# ATSAM3SD8B register map
Vendor: Atmel; File version: 0
CPU: CM3 r2p0, selectable endian, no MPU, no FPU, 0x4 interrupt priority bits, 0x0 interrupts
Registers are 32-bit, read-write, no defined reset value unless marked. A register's access mark holds for its fields unless they carry their own. Offsets are from the block's base; [hi:lo] are bit positions; {n}, {i} and the like mark numbered series.

## ADC — Analog-to-Digital Converter
Base 0x40038000; register names take the prefix ADC_
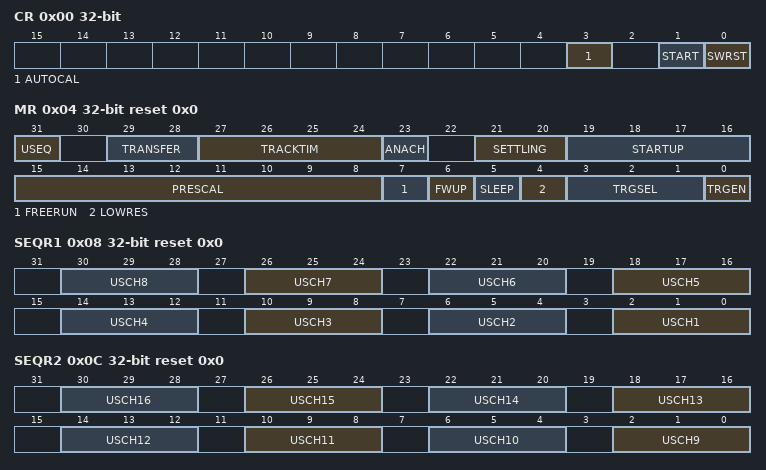
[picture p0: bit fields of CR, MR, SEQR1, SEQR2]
0x00 CR wo — Control Register
  [3] AUTOCAL — Automatic Calibration of ADC
  [1] START — Start Conversion
  [0] SWRST — Software Reset
0x04 MR reset 0x0 — Mode Register
  [31] USEQ — Use Sequence Enable
    0=NUM_ORDER (Normal Mode: The controller converts channels in a simple numeric order.); 1=REG_ORDER (User Sequence Mode: The sequence respects what is defined in ADC_SEQR1 and ADC_SEQR2 registers.)
  [29:28] TRANSFER — Transfer Period
  [27:24] TRACKTIM — Tracking Time
  [23] ANACH — Analog Change
    0=NONE (No analog change on channel switching: DIFF0, GAIN0 and OFF0 are used for all channels); 1=ALLOWED (Allows different analog settings for each channel. See ADC_CGR and ADC_COR Registers)
  [21:20] SETTLING — Analog Settling Time
    0=AST3 (3 periods of ADCClock); 1=AST5 (5 periods of ADCClock); 2=AST9 (9 periods of ADCClock); 3=AST17 (17 periods of ADCClock)
  [19:16] STARTUP — Start Up Time
    0=SUT0 (0 periods of ADCClock); 1=SUT8 (8 periods of ADCClock); 2=SUT16 (16 periods of ADCClock); 3=SUT24 (24 periods of ADCClock); 4=SUT64 (64 periods of ADCClock); 5=SUT80 (80 periods of ADCClock); 6=SUT96 (96 periods of ADCClock); 7=SUT112 (112 periods of ADCClock); 8=SUT512 (512 periods of ADCClock); 9=SUT576 (576 periods of ADCClock); 10=SUT640 (640 periods of ADCClock); 11=SUT704 (704 periods of ADCClock); 12=SUT768 (768 periods of ADCClock); 13=SUT832 (832 periods of ADCClock); 14=SUT896 (896 periods of ADCClock); 15=SUT960 (960 periods of ADCClock)
  [15:8] PRESCAL — Prescaler Rate Selection
  [7] FREERUN — Free Run Mode
    0=OFF (Normal Mode); 1=ON (Free Run Mode: Never wait for any trigger.)
  [6] FWUP — Fast Wake Up
    0=OFF (Normal Sleep Mode: The sleep mode is defined by the SLEEP bit); 1=ON (Fast Wake Up Sleep Mode: The Voltage reference is ON between conversions and ADC Core is OFF)
  [5] SLEEP — Sleep Mode
    0=NORMAL (Normal Mode: The ADC Core and reference voltage circuitry are kept ON between conversions); 1=SLEEP (Sleep Mode: The ADC Core and reference voltage circuitry are OFF between conversions)
  [4] LOWRES — Resolution
    0=BITS_12 (12-bit resolution); 1=BITS_10 (10-bit resolution)
  [3:1] TRGSEL — Trigger Selection
    0=ADC_TRIG0 (External trigger); 1=ADC_TRIG1 (TIO Output of the Timer Counter Channel 0); 2=ADC_TRIG2 (TIO Output of the Timer Counter Channel 1); 3=ADC_TRIG3 (TIO Output of the Timer Counter Channel 2); 4=ADC_TRIG4 (PWM Event Line 0); 5=ADC_TRIG5 (PWM Event Line 1)
  [0] TRGEN — Trigger Enable
    0=DIS (Hardware triggers are disabled. Starting a conversion is only possible by software.); 1=EN (Hardware trigger selected by TRGSEL field is enabled.)
0x08 SEQR1 reset 0x0 — Channel Sequence Register 1
  [4n-2:4n-4] USCH{n} (n=1..8) — User Sequence Number {n}
0x0C SEQR2 reset 0x0 — Channel Sequence Register 2
  [4n-34:4n-36] USCH{n} (n=9..16) — User Sequence Number {n}
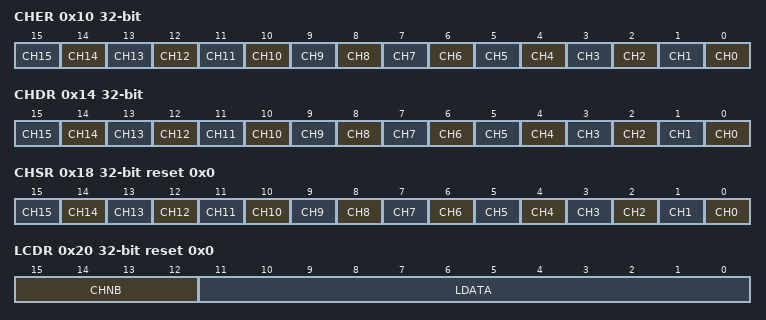
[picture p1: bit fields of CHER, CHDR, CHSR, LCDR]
0x10 CHER wo — Channel Enable Register
  [n] CH{n} (n=0..15) — Channel {n} Enable
0x14 CHDR wo — Channel Disable Register
  [n] CH{n} (n=0..15) — Channel {n} Disable
0x18 CHSR ro reset 0x0 — Channel Status Register
  [n] CH{n} (n=0..15) — Channel {n} Status
0x20 LCDR ro reset 0x0 — Last Converted Data Register
  [15:12] CHNB — Channel Number
  [11:0] LDATA — Last Data Converted
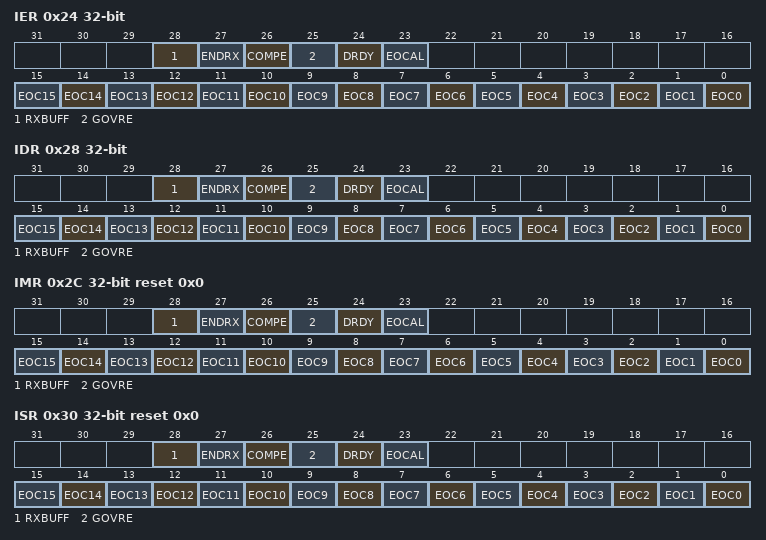
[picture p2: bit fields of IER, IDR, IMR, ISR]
0x24 IER wo — Interrupt Enable Register
  [28] RXBUFF — Receive Buffer Full Interrupt Enable
  [27] ENDRX — End of Receive Buffer Interrupt Enable
  [26] COMPE — Comparison Event Interrupt Enable
  [25] GOVRE — General Overrun Error Interrupt Enable
  [24] DRDY — Data Ready Interrupt Enable
  [23] EOCAL — End of Calibration Sequence
  [n] EOC{n} (n=0..15) — End of Conversion Interrupt Enable {n}
0x28 IDR wo — Interrupt Disable Register
  [28] RXBUFF — Receive Buffer Full Interrupt Disable
  [27] ENDRX — End of Receive Buffer Interrupt Disable
  [26] COMPE — Comparison Event Interrupt Disable
  [25] GOVRE — General Overrun Error Interrupt Disable
  [24] DRDY — Data Ready Interrupt Disable
  [23] EOCAL — End of Calibration Sequence
  [n] EOC{n} (n=0..15) — End of Conversion Interrupt Disable {n}
0x2C IMR ro reset 0x0 — Interrupt Mask Register
  [28] RXBUFF — Receive Buffer Full Interrupt Mask
  [27] ENDRX — End of Receive Buffer Interrupt Mask
  [26] COMPE — Comparison Event Interrupt Mask
  [25] GOVRE — General Overrun Error Interrupt Mask
  [24] DRDY — Data Ready Interrupt Mask
  [23] EOCAL — End of Calibration Sequence
  [n] EOC{n} (n=0..15) — End of Conversion Interrupt Mask {n}
0x30 ISR ro reset 0x0 — Interrupt Status Register
  [28] RXBUFF — RX Buffer Full
  [27] ENDRX — End of RX Buffer
  [26] COMPE — Comparison Error
  [25] GOVRE — General Overrun Error
  [24] DRDY — Data Ready
  [23] EOCAL — End of Calibration Sequence
  [n] EOC{n} (n=0..15) — End of Conversion {n}
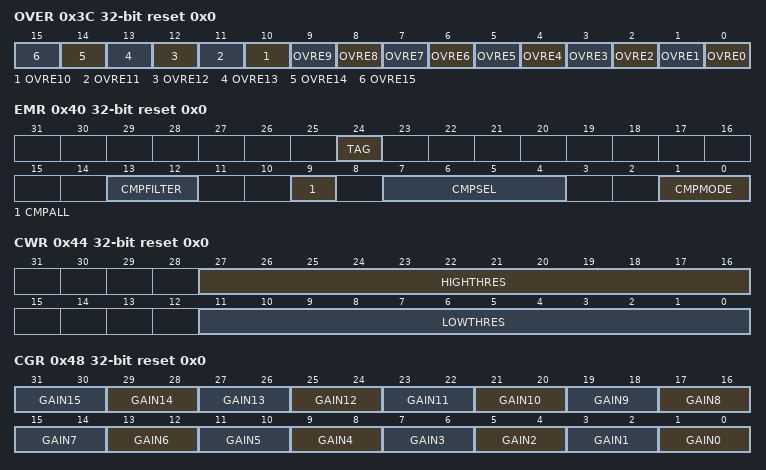
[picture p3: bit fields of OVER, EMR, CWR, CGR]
0x3C OVER ro reset 0x0 — Overrun Status Register
  [n] OVRE{n} (n=0..15) — Overrun Error {n}
0x40 EMR reset 0x0 — Extended Mode Register
  [24] TAG — TAG of ADC_LDCR register
  [13:12] CMPFILTER — Compare Event Filtering
  [9] CMPALL — Compare All Channels
  [7:4] CMPSEL — Comparison Selected Channel
  [1:0] CMPMODE — Comparison Mode
    0=LOW (Generates an event when the converted data is lower than the low threshold of the window.); 1=HIGH (Generates an event when the converted data is higher than the high threshold of the window.); 2=IN (Generates an event when the converted data is in the comparison window.); 3=OUT (Generates an event when the converted data is out of the comparison window.)
0x44 CWR reset 0x0 — Compare Window Register
  [27:16] HIGHTHRES — High Threshold
  [11:0] LOWTHRES — Low Threshold
0x48 CGR reset 0x0 — Channel Gain Register
  [2n+1:2n] GAIN{n} (n=0..15) — Gain for channel {n}
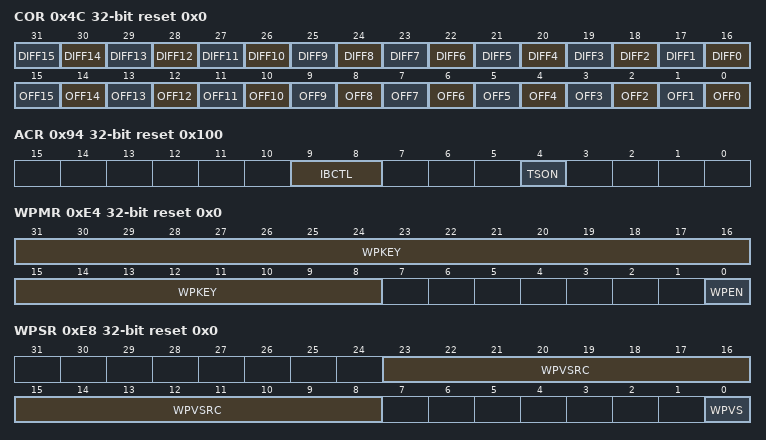
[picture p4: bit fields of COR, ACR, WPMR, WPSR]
0x4C COR reset 0x0 — Channel Offset Register
  [n+16] DIFF{n} (n=0..15) — Differential inputs for channel {n}
  [n] OFF{n} (n=0..15) — Offset for channel {n}
{0x50+4i} CDR[{i}] ro (i=0..14) — Channel Data Register
  [11:0] DATA — Converted Data
0x94 ACR reset 0x100 — Analog Control Register
  [9:8] IBCTL — ADC Bias Current Control
  [4] TSON — Temperature Sensor On
0xE4 WPMR reset 0x0 — Write Protect Mode Register
  [31:8] WPKEY — Write Protect KEY
  [0] WPEN — Write Protect Enable
0xE8 WPSR ro reset 0x0 — Write Protect Status Register
  [23:8] WPVSRC — Write Protect Violation Source
  [0] WPVS — Write Protect Violation Status
0x100 RPR reset 0x0 — Receive Pointer Register
  [31:0] RXPTR
0x104 RCR reset 0x0 — Receive Counter Register
  [15:0] RXCTR
0x110 RNPR reset 0x0 — Receive Next Pointer Register
  [31:0] RXNPTR — Receive Next Pointer
0x114 RNCR reset 0x0 — Receive Next Counter Register
  [15:0] RXNCTR — Receive Next Counter
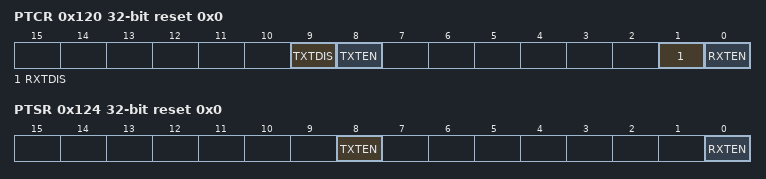
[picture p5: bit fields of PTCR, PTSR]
0x120 PTCR wo reset 0x0 — Transfer Control Register
  [9] TXTDIS — Transmitter Transfer Disable
  [8] TXTEN — Transmitter Transfer Enable
  [1] RXTDIS — Receiver Transfer Disable
  [0] RXTEN — Receiver Transfer Enable
0x124 PTSR ro reset 0x0 — Transfer Status Register
  [8] TXTEN — Transmitter Transfer Enable
  [0] RXTEN — Receiver Transfer Enable
